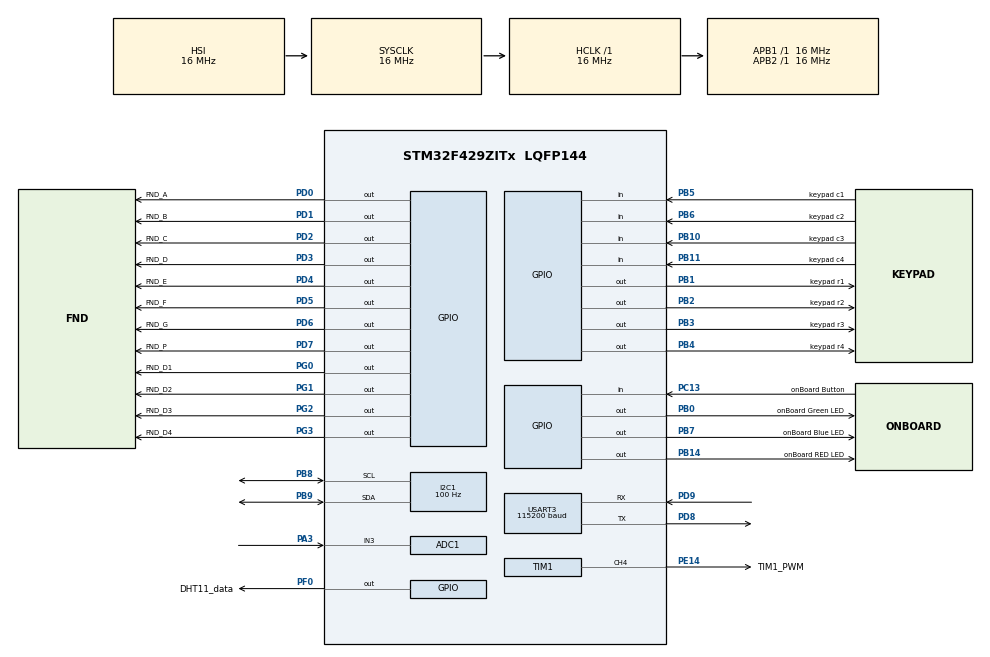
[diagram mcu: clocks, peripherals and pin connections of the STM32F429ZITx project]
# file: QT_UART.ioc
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ADC1.Channel-0\#ChannelRegularConversion=ADC_CHANNEL_3
ADC1.ContinuousConvMode=ENABLE
ADC1.EOCSelection=ADC_EOC_SEQ_CONV
ADC1.NbrOfConversionFlag=1
ADC1.Rank-0\#ChannelRegularConversion=1
ADC1.SamplingTime-0\#ChannelRegularConversion=ADC_SAMPLETIME_144CYCLES
ADC1.ScanConvMode=ENABLE
ADC1.master=1
I2C1.ClockSpeed=100
Mcu.Family=STM32F4
Mcu.Name=STM32F429ZITx
Mcu.Package=LQFP144
NVIC.ADC_IRQn=true\:5\:0\:true\:false\:true\:true\:true
NVIC.I2C1_ER_IRQn=true\:0\:0\:false\:false\:true\:true\:true
NVIC.I2C1_EV_IRQn=true\:0\:0\:false\:false\:true\:true\:true
NVIC.PriorityGroup=NVIC_PRIORITYGROUP_4
NVIC.TIM2_IRQn=true\:0\:0\:true\:false\:true\:true\:true
NVIC.USART3_IRQn=true\:2\:0\:true\:false\:true\:true\:true
PA3.Signal=ADCx_IN3
PB0.GPIO_Label=onBoard Green LED
PB0.Signal=GPIO_Output
PB1.GPIO_Label=keypad r1
PB1.Signal=GPIO_Output
PB10.GPIO_Label=keypad c3
PB10.GPIO_PuPd=GPIO_PULLDOWN
PB10.Signal=GPIO_Input
PB11.GPIO_Label=keypad c4
PB11.GPIO_PuPd=GPIO_PULLDOWN
PB11.Signal=GPIO_Input
PB14.GPIO_Label=onBoard RED LED
PB14.Signal=GPIO_Output
PB2/BOOT1.GPIO_Label=keypad r2
PB2/BOOT1.Signal=GPIO_Output
PB3.GPIO_Label=keypad r3
PB3.Signal=GPIO_Output
PB4.GPIO_Label=keypad r4
PB4.Signal=GPIO_Output
PB5.GPIO_Label=keypad c1
PB5.GPIO_PuPd=GPIO_PULLDOWN
PB5.Signal=GPIO_Input
PB6.GPIO_Label=keypad c2
PB6.GPIO_PuPd=GPIO_PULLDOWN
PB6.Signal=GPIO_Input
PB7.GPIO_Label=onBoard Blue LED
PB7.Signal=GPIO_Output
PB8.Mode=I2C
PB8.Signal=I2C1_SCL
PB9.Mode=I2C
PB9.Signal=I2C1_SDA
PC13.GPIO_Label=onBoard Button
PC13.Signal=GPIO_Input
PD0.GPIO_Label=FND_A
PD0.Signal=GPIO_Output
PD1.GPIO_Label=FND_B
PD1.Signal=GPIO_Output
PD2.GPIO_Label=FND_C
PD2.Signal=GPIO_Output
PD3.GPIO_Label=FND_D
PD3.Signal=GPIO_Output
PD4.GPIO_Label=FND_E
PD4.Signal=GPIO_Output
PD5.GPIO_Label=FND_F
PD5.Signal=GPIO_Output
PD6.GPIO_Label=FND_G
PD6.Signal=GPIO_Output
PD7.GPIO_Label=FND_P
PD7.Signal=GPIO_Output
PD8.Mode=Asynchronous
PD8.Signal=USART3_TX
PD9.Mode=Asynchronous
PD9.Signal=USART3_RX
PE14.GPIO_Label=TIM1_PWM
PE14.Signal=S_TIM1_CH4
PF0.GPIO_Label=DHT11_data
PF0.Signal=GPIO_Output
PG0.GPIO_Label=FND_D1
PG0.Signal=GPIO_Output
PG1.GPIO_Label=FND_D2
PG1.Signal=GPIO_Output
PG2.GPIO_Label=FND_D3
PG2.Signal=GPIO_Output
PG3.GPIO_Label=FND_D4
PG3.Signal=GPIO_Output
ProjectManager.HeapSize=0x200
ProjectManager.StackSize=0x400
ProjectManager.TargetToolchain=TrueSTUDIO
RCC.AHBFreq_Value=16000000
RCC.APB1Freq_Value=16000000
RCC.APB1TimFreq_Value=16000000
RCC.APB2Freq_Value=16000000
RCC.APB2TimFreq_Value=16000000
RCC.CortexFreq_Value=16000000
RCC.HCLKFreq_Value=16000000
RCC.HSE_VALUE=25000000
RCC.HSI_VALUE=16000000
RCC.LSE_VALUE=32768
RCC.SYSCLKFreq_VALUE=16000000
RCC.VCOOutputFreq_Value=192000000
SH.ADCx_IN3.0=ADC1_IN3,IN3
SH.S_TIM1_CH4.0=TIM1_CH4,PWM Generation4 CH4
TIM1.Channel-PWM\ Generation4\ CH4=TIM_CHANNEL_4
TIM1.Period=4999
TIM1.Prescaler=63
TIM1.Pulse-PWM\ Generation4\ CH4=499
TIM2.Channel-Output\ Compare2\ No\ Output=TIM_CHANNEL_2
TIM2.Period=999
TIM2.Prescaler=15
USART3.BaudRate=115200
USART3.VirtualMode=VM_ASYNC
VP_TIM1_VS_ClockSourceINT.Mode=Internal
VP_TIM2_VS_ClockSourceINT.Mode=Internal
VP_TIM2_VS_no_output2.Mode=Output Compare2 No Output
board=custom

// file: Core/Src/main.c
/* USER CODE BEGIN Header */
/**
  ******************************************************************************
  * @file           : main.c
  * @brief          : Main program body
  ******************************************************************************
  * @attention
  *
  * <h2><center>&copy; Copyright (c) 2019 STMicroelectronics.
  * All rights reserved.</center></h2>
  *
  * This software component is licensed by ST under BSD 3-Clause license,
  * the "License"; You may not use this file except in compliance with the
  * License. You may obtain a copy of the License at:
  *                        opensource.org/licenses/BSD-3-Clause
  *
  ******************************************************************************
  */
/* USER CODE END Header */

#include "main.h"

/* USER CODE BEGIN Includes */
#include <stdio.h>
#include <stdlib.h>
/* USER CODE END Includes */

ADC_HandleTypeDef hadc1;

I2C_HandleTypeDef hi2c1;

TIM_HandleTypeDef htim1;
TIM_HandleTypeDef htim2;

UART_HandleTypeDef huart3;

void SystemClock_Config(void);
static void MX_GPIO_Init(void);
static void MX_TIM2_Init(void);
static void MX_USART3_UART_Init(void);
static void MX_ADC1_Init(void);
static void MX_TIM1_Init(void);
static void MX_I2C1_Init(void);
/* USER CODE BEGIN PFP */
extern void UART_main();
/* USER CODE END PFP */

int main(void)
{

  /* MCU Configuration--------------------------------------------------------*/

  /* Reset of all peripherals, Initializes the Flash interface and the Systick. */
  HAL_Init();

  /* Configure the system clock */
  SystemClock_Config();

  /* Initialize all configured peripherals */
  MX_GPIO_Init();
  MX_TIM2_Init();
  MX_USART3_UART_Init();
  MX_ADC1_Init();
  MX_TIM1_Init();
  MX_I2C1_Init();
  /* USER CODE BEGIN 2 */
  // 버퍼 사이즈 초기화, 개행문자 안붙여도 됨
  setvbuf(stdout, NULL, _IONBF, 0);

  /* USER CODE END 2 */

  /* Infinite loop */
  /* USER CODE BEGIN WHILE */
  UART_main();
  while (1)
  {
    /* USER CODE END WHILE */

  }
}

void SystemClock_Config(void)
{
  RCC_OscInitTypeDef RCC_OscInitStruct = {0};
  RCC_ClkInitTypeDef RCC_ClkInitStruct = {0};

  /** Configure the main internal regulator output voltage
  */
  __HAL_RCC_PWR_CLK_ENABLE();
  __HAL_PWR_VOLTAGESCALING_CONFIG(PWR_REGULATOR_VOLTAGE_SCALE3);
  /** Initializes the CPU, AHB and APB busses clocks
  */
  RCC_OscInitStruct.OscillatorType = RCC_OSCILLATORTYPE_HSI;
  RCC_OscInitStruct.HSIState = RCC_HSI_ON;
  RCC_OscInitStruct.HSICalibrationValue = RCC_HSICALIBRATION_DEFAULT;
  RCC_OscInitStruct.PLL.PLLState = RCC_PLL_NONE;
  if (HAL_RCC_OscConfig(&RCC_OscInitStruct) != HAL_OK)
  {
    Error_Handler();
  }
  /** Initializes the CPU, AHB and APB busses clocks
  */
  RCC_ClkInitStruct.ClockType = RCC_CLOCKTYPE_HCLK|RCC_CLOCKTYPE_SYSCLK
                              |RCC_CLOCKTYPE_PCLK1|RCC_CLOCKTYPE_PCLK2;
  RCC_ClkInitStruct.SYSCLKSource = RCC_SYSCLKSOURCE_HSI;
  RCC_ClkInitStruct.AHBCLKDivider = RCC_SYSCLK_DIV1;
  RCC_ClkInitStruct.APB1CLKDivider = RCC_HCLK_DIV1;
  RCC_ClkInitStruct.APB2CLKDivider = RCC_HCLK_DIV1;

  if (HAL_RCC_ClockConfig(&RCC_ClkInitStruct, FLASH_LATENCY_0) != HAL_OK)
  {
    Error_Handler();
  }
}

static void MX_ADC1_Init(void)
{

  ADC_ChannelConfTypeDef sConfig = {0};

  /** Configure the global features of the ADC (Clock, Resolution, Data Alignment and number of conversion)
  */
  hadc1.Instance = ADC1;
  hadc1.Init.ClockPrescaler = ADC_CLOCK_SYNC_PCLK_DIV2;
  hadc1.Init.Resolution = ADC_RESOLUTION_12B;
  hadc1.Init.ScanConvMode = ENABLE;
  hadc1.Init.ContinuousConvMode = ENABLE;
  hadc1.Init.DiscontinuousConvMode = DISABLE;
  hadc1.Init.ExternalTrigConvEdge = ADC_EXTERNALTRIGCONVEDGE_NONE;
  hadc1.Init.ExternalTrigConv = ADC_SOFTWARE_START;
  hadc1.Init.DataAlign = ADC_DATAALIGN_RIGHT;
  hadc1.Init.NbrOfConversion = 1;
  hadc1.Init.DMAContinuousRequests = DISABLE;
  hadc1.Init.EOCSelection = ADC_EOC_SEQ_CONV;
  if (HAL_ADC_Init(&hadc1) != HAL_OK)
  {
    Error_Handler();
  }
  /** Configure for the selected ADC regular channel its corresponding rank in the sequencer and its sample time.
  */
  sConfig.Channel = ADC_CHANNEL_3;
  sConfig.Rank = 1;
  sConfig.SamplingTime = ADC_SAMPLETIME_144CYCLES;
  if (HAL_ADC_ConfigChannel(&hadc1, &sConfig) != HAL_OK)
  {
    Error_Handler();
  }

}

static void MX_I2C1_Init(void)
{

  hi2c1.Instance = I2C1;
  hi2c1.Init.ClockSpeed = 100;
  hi2c1.Init.DutyCycle = I2C_DUTYCYCLE_2;
  hi2c1.Init.OwnAddress1 = 0;
  hi2c1.Init.AddressingMode = I2C_ADDRESSINGMODE_7BIT;
  hi2c1.Init.DualAddressMode = I2C_DUALADDRESS_DISABLE;
  hi2c1.Init.OwnAddress2 = 0;
  hi2c1.Init.GeneralCallMode = I2C_GENERALCALL_DISABLE;
  hi2c1.Init.NoStretchMode = I2C_NOSTRETCH_DISABLE;
  if (HAL_I2C_Init(&hi2c1) != HAL_OK)
  {
    Error_Handler();
  }
  /** Configure Analogue filter
  */
  if (HAL_I2CEx_ConfigAnalogFilter(&hi2c1, I2C_ANALOGFILTER_ENABLE) != HAL_OK)
  {
    Error_Handler();
  }
  /** Configure Digital filter
  */
  if (HAL_I2CEx_ConfigDigitalFilter(&hi2c1, 0) != HAL_OK)
  {
    Error_Handler();
  }

}

static void MX_TIM1_Init(void)
{

  TIM_ClockConfigTypeDef sClockSourceConfig = {0};
  TIM_MasterConfigTypeDef sMasterConfig = {0};
  TIM_OC_InitTypeDef sConfigOC = {0};
  TIM_BreakDeadTimeConfigTypeDef sBreakDeadTimeConfig = {0};

  htim1.Instance = TIM1;
  htim1.Init.Prescaler = 63;
  htim1.Init.CounterMode = TIM_COUNTERMODE_UP;
  htim1.Init.Period = 4999;
  htim1.Init.ClockDivision = TIM_CLOCKDIVISION_DIV1;
  htim1.Init.RepetitionCounter = 0;
  htim1.Init.AutoReloadPreload = TIM_AUTORELOAD_PRELOAD_DISABLE;
  if (HAL_TIM_Base_Init(&htim1) != HAL_OK)
  {
    Error_Handler();
  }
  sClockSourceConfig.ClockSource = TIM_CLOCKSOURCE_INTERNAL;
  if (HAL_TIM_ConfigClockSource(&htim1, &sClockSourceConfig) != HAL_OK)
  {
    Error_Handler();
  }
  if (HAL_TIM_PWM_Init(&htim1) != HAL_OK)
  {
    Error_Handler();
  }
  sMasterConfig.MasterOutputTrigger = TIM_TRGO_RESET;
  sMasterConfig.MasterSlaveMode = TIM_MASTERSLAVEMODE_DISABLE;
  if (HAL_TIMEx_MasterConfigSynchronization(&htim1, &sMasterConfig) != HAL_OK)
  {
    Error_Handler();
  }
  sConfigOC.OCMode = TIM_OCMODE_PWM1;
  sConfigOC.Pulse = 499;
  sConfigOC.OCPolarity = TIM_OCPOLARITY_HIGH;
  sConfigOC.OCFastMode = TIM_OCFAST_DISABLE;
  sConfigOC.OCIdleState = TIM_OCIDLESTATE_RESET;
  sConfigOC.OCNIdleState = TIM_OCNIDLESTATE_RESET;
  if (HAL_TIM_PWM_ConfigChannel(&htim1, &sConfigOC, TIM_CHANNEL_4) != HAL_OK)
  {
    Error_Handler();
  }
  sBreakDeadTimeConfig.OffStateRunMode = TIM_OSSR_DISABLE;
  sBreakDeadTimeConfig.OffStateIDLEMode = TIM_OSSI_DISABLE;
  sBreakDeadTimeConfig.LockLevel = TIM_LOCKLEVEL_OFF;
  sBreakDeadTimeConfig.DeadTime = 0;
  sBreakDeadTimeConfig.BreakState = TIM_BREAK_DISABLE;
  sBreakDeadTimeConfig.BreakPolarity = TIM_BREAKPOLARITY_HIGH;
  sBreakDeadTimeConfig.AutomaticOutput = TIM_AUTOMATICOUTPUT_DISABLE;
  if (HAL_TIMEx_ConfigBreakDeadTime(&htim1, &sBreakDeadTimeConfig) != HAL_OK)
  {
    Error_Handler();
  }
  HAL_TIM_MspPostInit(&htim1);

}

static void MX_TIM2_Init(void)
{

  TIM_ClockConfigTypeDef sClockSourceConfig = {0};
  TIM_MasterConfigTypeDef sMasterConfig = {0};
  TIM_OC_InitTypeDef sConfigOC = {0};

  htim2.Instance = TIM2;
  htim2.Init.Prescaler = 15;
  htim2.Init.CounterMode = TIM_COUNTERMODE_UP;
  htim2.Init.Period = 999;
  htim2.Init.ClockDivision = TIM_CLOCKDIVISION_DIV1;
  htim2.Init.AutoReloadPreload = TIM_AUTORELOAD_PRELOAD_DISABLE;
  if (HAL_TIM_Base_Init(&htim2) != HAL_OK)
  {
    Error_Handler();
  }
  sClockSourceConfig.ClockSource = TIM_CLOCKSOURCE_INTERNAL;
  if (HAL_TIM_ConfigClockSource(&htim2, &sClockSourceConfig) != HAL_OK)
  {
    Error_Handler();
  }
  if (HAL_TIM_OC_Init(&htim2) != HAL_OK)
  {
    Error_Handler();
  }
  sMasterConfig.MasterOutputTrigger = TIM_TRGO_RESET;
  sMasterConfig.MasterSlaveMode = TIM_MASTERSLAVEMODE_DISABLE;
  if (HAL_TIMEx_MasterConfigSynchronization(&htim2, &sMasterConfig) != HAL_OK)
  {
    Error_Handler();
  }
  sConfigOC.OCMode = TIM_OCMODE_TIMING;
  sConfigOC.Pulse = 0;
  sConfigOC.OCPolarity = TIM_OCPOLARITY_HIGH;
  sConfigOC.OCFastMode = TIM_OCFAST_DISABLE;
  if (HAL_TIM_OC_ConfigChannel(&htim2, &sConfigOC, TIM_CHANNEL_2) != HAL_OK)
  {
    Error_Handler();
  }

}

static void MX_USART3_UART_Init(void)
{

  huart3.Instance = USART3;
  huart3.Init.BaudRate = 115200;
  huart3.Init.WordLength = UART_WORDLENGTH_8B;
  huart3.Init.StopBits = UART_STOPBITS_1;
  huart3.Init.Parity = UART_PARITY_NONE;
  huart3.Init.Mode = UART_MODE_TX_RX;
  huart3.Init.HwFlowCtl = UART_HWCONTROL_NONE;
  huart3.Init.OverSampling = UART_OVERSAMPLING_16;
  if (HAL_UART_Init(&huart3) != HAL_OK)
  {
    Error_Handler();
  }

}

static void MX_GPIO_Init(void)
{
  GPIO_InitTypeDef GPIO_InitStruct = {0};

  /* GPIO Ports Clock Enable */
  __HAL_RCC_GPIOC_CLK_ENABLE();
  __HAL_RCC_GPIOF_CLK_ENABLE();
  __HAL_RCC_GPIOA_CLK_ENABLE();
  __HAL_RCC_GPIOB_CLK_ENABLE();
  __HAL_RCC_GPIOG_CLK_ENABLE();
  __HAL_RCC_GPIOE_CLK_ENABLE();
  __HAL_RCC_GPIOD_CLK_ENABLE();

  /*Configure GPIO pin Output Level */
  HAL_GPIO_WritePin(DHT11_data_GPIO_Port, DHT11_data_Pin, GPIO_PIN_RESET);

  /*Configure GPIO pin Output Level */
  HAL_GPIO_WritePin(GPIOB, onBoard_Green_LED_Pin|keypad_r1_Pin|keypad_r2_Pin|onBoard_RED_LED_Pin
                          |keypad_r3_Pin|keypad_r4_Pin|onBoard_Blue_LED_Pin, GPIO_PIN_RESET);

  /*Configure GPIO pin Output Level */
  HAL_GPIO_WritePin(GPIOG, FND_D1_Pin|FND_D2_Pin|FND_D3_Pin|FND_D4_Pin, GPIO_PIN_RESET);

  /*Configure GPIO pin Output Level */
  HAL_GPIO_WritePin(GPIOD, FND_A_Pin|FND_B_Pin|FND_C_Pin|FND_D_Pin
                          |FND_E_Pin|FND_F_Pin|FND_G_Pin|FND_P_Pin, GPIO_PIN_RESET);

  /*Configure GPIO pin : onBoard_Button_Pin */
  GPIO_InitStruct.Pin = onBoard_Button_Pin;
  GPIO_InitStruct.Mode = GPIO_MODE_INPUT;
  GPIO_InitStruct.Pull = GPIO_NOPULL;
  HAL_GPIO_Init(onBoard_Button_GPIO_Port, &GPIO_InitStruct);

  /*Configure GPIO pin : DHT11_data_Pin */
  GPIO_InitStruct.Pin = DHT11_data_Pin;
  GPIO_InitStruct.Mode = GPIO_MODE_OUTPUT_PP;
  GPIO_InitStruct.Pull = GPIO_NOPULL;
  GPIO_InitStruct.Speed = GPIO_SPEED_FREQ_LOW;
  HAL_GPIO_Init(DHT11_data_GPIO_Port, &GPIO_InitStruct);

  /*Configure GPIO pins : onBoard_Green_LED_Pin keypad_r1_Pin keypad_r2_Pin onBoard_RED_LED_Pin
                           keypad_r3_Pin keypad_r4_Pin onBoard_Blue_LED_Pin */
  GPIO_InitStruct.Pin = onBoard_Green_LED_Pin|keypad_r1_Pin|keypad_r2_Pin|onBoard_RED_LED_Pin
                          |keypad_r3_Pin|keypad_r4_Pin|onBoard_Blue_LED_Pin;
  GPIO_InitStruct.Mode = GPIO_MODE_OUTPUT_PP;
  GPIO_InitStruct.Pull = GPIO_NOPULL;
  GPIO_InitStruct.Speed = GPIO_SPEED_FREQ_LOW;
  HAL_GPIO_Init(GPIOB, &GPIO_InitStruct);

  /*Configure GPIO pins : FND_D1_Pin FND_D2_Pin FND_D3_Pin FND_D4_Pin */
  GPIO_InitStruct.Pin = FND_D1_Pin|FND_D2_Pin|FND_D3_Pin|FND_D4_Pin;
  GPIO_InitStruct.Mode = GPIO_MODE_OUTPUT_PP;
  GPIO_InitStruct.Pull = GPIO_NOPULL;
  GPIO_InitStruct.Speed = GPIO_SPEED_FREQ_LOW;
  HAL_GPIO_Init(GPIOG, &GPIO_InitStruct);

  /*Configure GPIO pins : keypad_c3_Pin keypad_c4_Pin keypad_c1_Pin keypad_c2_Pin */
  GPIO_InitStruct.Pin = keypad_c3_Pin|keypad_c4_Pin|keypad_c1_Pin|keypad_c2_Pin;
  GPIO_InitStruct.Mode = GPIO_MODE_INPUT;
  GPIO_InitStruct.Pull = GPIO_PULLDOWN;
  HAL_GPIO_Init(GPIOB, &GPIO_InitStruct);

  /*Configure GPIO pins : FND_A_Pin FND_B_Pin FND_C_Pin FND_D_Pin
                           FND_E_Pin FND_F_Pin FND_G_Pin FND_P_Pin */
  GPIO_InitStruct.Pin = FND_A_Pin|FND_B_Pin|FND_C_Pin|FND_D_Pin
                          |FND_E_Pin|FND_F_Pin|FND_G_Pin|FND_P_Pin;
  GPIO_InitStruct.Mode = GPIO_MODE_OUTPUT_PP;
  GPIO_InitStruct.Pull = GPIO_NOPULL;
  GPIO_InitStruct.Speed = GPIO_SPEED_FREQ_LOW;
  HAL_GPIO_Init(GPIOD, &GPIO_InitStruct);

}

/* USER CODE BEGIN 4 */
int _write(int file, unsigned char* p, int len)
{
   HAL_UART_Transmit(&huart3, p, len, 10);
   return len;
}

/* USER CODE END 4 */

void Error_Handler(void)
{
}

/************************ (C) COPYRIGHT STMicroelectronics *****END OF FILE****/
